# CTRL_MODULE_CORE_PAD register map
Vendor: Texas Instruments
Registers are 32-bit, access per field, reset 0x10F010F unless marked. A register's access mark holds for its fields unless they carry their own. Offsets are as the file gives them; [hi:lo] are bit positions; 'fields as' and 'values as' point back to an identical list.

## CTRL_MODULE_CORE_PAD (part 2 of 7)
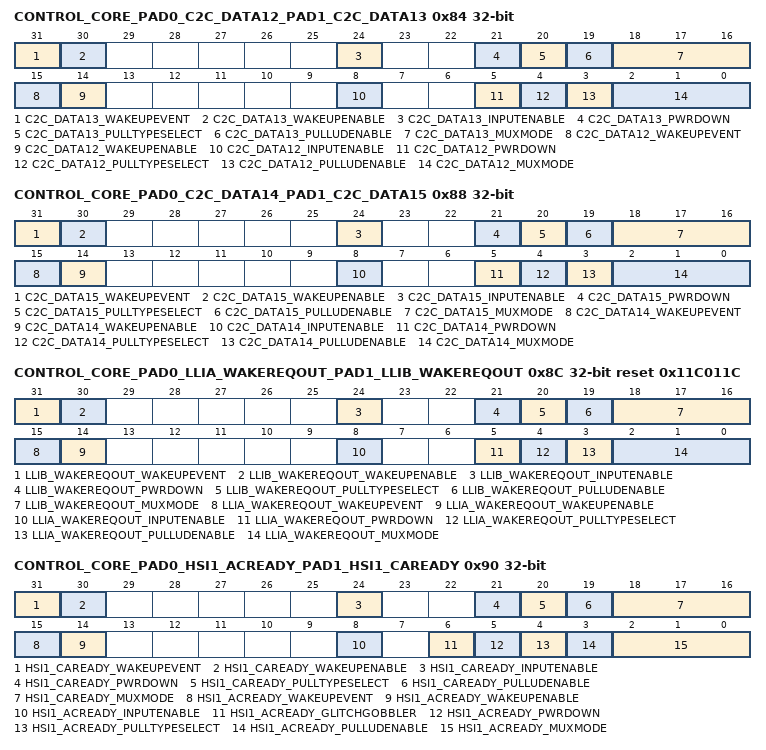
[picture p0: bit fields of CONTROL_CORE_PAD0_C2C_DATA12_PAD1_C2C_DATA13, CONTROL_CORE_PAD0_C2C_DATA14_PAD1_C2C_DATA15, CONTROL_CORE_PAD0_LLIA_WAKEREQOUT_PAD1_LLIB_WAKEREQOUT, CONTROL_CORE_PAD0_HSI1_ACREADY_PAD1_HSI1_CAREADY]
0x84 CONTROL_CORE_PAD0_C2C_DATA12_PAD1_C2C_DATA13 — Register control for Pads c2c_data12 and c2c_data13 Access conditions. Read: unrestricted, Write: unrestricted
  [31] C2C_DATA13_WAKEUPEVENT ro — Pad_x wake-up event status latched in the IO
    1=WakeUp (A wake-up event occurred); 0=No wake-up event occurred
  [30] C2C_DATA13_WAKEUPENABLE rw — Input pad wake-up enable
    0=DetectLow (wake-up detection is disabled); 1=DetectLowHigh (wake-up detection is enabled)
  [24] C2C_DATA13_INPUTENABLE rw — Input enable value for pad c2c_data13
    0=InputBufferDisabled (Input buffer of IO cell is disabled); 1=InputBufferEnabled (Input buffer of IO cell is enabled)
  [21] C2C_DATA13_PWRDOWN rw — Power Down setting for pad c2c_data13
    0=PwrDownDisabled (IO cell power is ON); 1=PwrDownEnabled (IO cell power is OFF)
  [20] C2C_DATA13_PULLTYPESELECT rw — Pull-Up/Down selection for pad c2c_data13
    0=Pull-Down selected; 1=Pull-Up selected
  [19] C2C_DATA13_PULLUDENABLE rw — Pull-Up/Down enable for pad c2c_data13
    0=PullDisabled (Pull-Up/Down disabled); 1=PullEnabled (Pull-Up/Down enabled)
  [18:16] C2C_DATA13_MUXMODE rw — Functional multiplexing selection for pad c2c_data13
    0=SEL_C2C_DATA13 (Reserved); 6=SEL_GPIO4_118 (Select gpio4_118); 4=SEL_GPMC_A21 (Select gpmc_a21); 7=SEL_SAFE_MODE_CORE35 (Select safe_mode_core35); 5=SEL_HW_DBG29 (Select hw_dbg29)
  [15] C2C_DATA12_WAKEUPEVENT ro — Pad_x wake-up event status latched in the IO
    values as C2C_DATA13_WAKEUPEVENT
  [14] C2C_DATA12_WAKEUPENABLE rw — Input pad wake-up enable
    values as C2C_DATA13_WAKEUPENABLE
  [8] C2C_DATA12_INPUTENABLE rw — Input enable value for pad c2c_data12
    values as C2C_DATA13_INPUTENABLE
  [5] C2C_DATA12_PWRDOWN rw — Power Down setting for pad c2c_data12
    values as C2C_DATA13_PWRDOWN
  [4] C2C_DATA12_PULLTYPESELECT rw — Pull-Up/Down selection for pad c2c_data12
    0=Pull-Down selected; 1=Pull-Up selected
  [3] C2C_DATA12_PULLUDENABLE rw — Pull-Up/Down enable for pad c2c_data12
    values as C2C_DATA13_PULLUDENABLE
  [2:0] C2C_DATA12_MUXMODE rw — Functional multiplexing selection for pad c2c_data12
    0=SEL_C2C_DATA12 (Reserved); 6=SEL_GPIO4_117 (Select gpio4_117); 4=SEL_GPMC_A20 (Select gpmc_a20); 7=SEL_SAFE_MODE_CORE34 (Select safe_mode_core34); 5=SEL_HW_DBG28 (Select hw_dbg28)
0x88 CONTROL_CORE_PAD0_C2C_DATA14_PAD1_C2C_DATA15 — Register control for Pads c2c_data14 and c2c_data15 Access conditions. Read: unrestricted, Write: unrestricted
  [31] C2C_DATA15_WAKEUPEVENT ro — Pad_x wake-up event status latched in the IO
    values as CONTROL_CORE_PAD0_C2C_DATA12_PAD1_C2C_DATA13.C2C_DATA13_WAKEUPEVENT
  [30] C2C_DATA15_WAKEUPENABLE rw — Input pad wake-up enable
    values as CONTROL_CORE_PAD0_C2C_DATA12_PAD1_C2C_DATA13.C2C_DATA13_WAKEUPENABLE
  [24] C2C_DATA15_INPUTENABLE rw — Input enable value for pad c2c_data15
    values as CONTROL_CORE_PAD0_C2C_DATA12_PAD1_C2C_DATA13.C2C_DATA13_INPUTENABLE
  [21] C2C_DATA15_PWRDOWN rw — Power Down setting for pad c2c_data15
    values as CONTROL_CORE_PAD0_C2C_DATA12_PAD1_C2C_DATA13.C2C_DATA13_PWRDOWN
  [20] C2C_DATA15_PULLTYPESELECT rw — Pull-Up/Down selection for pad c2c_data15
    0=Pull-Down selected; 1=Pull-Up selected
  [19] C2C_DATA15_PULLUDENABLE rw — Pull-Up/Down enable for pad c2c_data15
    values as CONTROL_CORE_PAD0_C2C_DATA12_PAD1_C2C_DATA13.C2C_DATA13_PULLUDENABLE
  [18:16] C2C_DATA15_MUXMODE rw — Functional multiplexing selection for pad c2c_data15
    0=SEL_C2C_DATA15 (Reserved); 6=SEL_GPIO4_120 (Select gpio4_120); 4=SEL_GPMC_A23 (Select gpmc_a23); 7=SEL_SAFE_MODE_CORE37 (Select safe_mode_core37); 5=SEL_HW_DBG31 (Select hw_dbg31)
  [15] C2C_DATA14_WAKEUPEVENT ro — Pad_x wake-up event status latched in the IO
    values as CONTROL_CORE_PAD0_C2C_DATA12_PAD1_C2C_DATA13.C2C_DATA13_WAKEUPEVENT
  [14] C2C_DATA14_WAKEUPENABLE rw — Input pad wake-up enable
    values as CONTROL_CORE_PAD0_C2C_DATA12_PAD1_C2C_DATA13.C2C_DATA13_WAKEUPENABLE
  [8] C2C_DATA14_INPUTENABLE rw — Input enable value for pad c2c_data14
    values as CONTROL_CORE_PAD0_C2C_DATA12_PAD1_C2C_DATA13.C2C_DATA13_INPUTENABLE
  [5] C2C_DATA14_PWRDOWN rw — Power Down setting for pad c2c_data14
    values as CONTROL_CORE_PAD0_C2C_DATA12_PAD1_C2C_DATA13.C2C_DATA13_PWRDOWN
  [4] C2C_DATA14_PULLTYPESELECT rw — Pull-Up/Down selection for pad c2c_data14
    0=Pull-Down selected; 1=Pull-Up selected
  [3] C2C_DATA14_PULLUDENABLE rw — Pull-Up/Down enable for pad c2c_data14
    values as CONTROL_CORE_PAD0_C2C_DATA12_PAD1_C2C_DATA13.C2C_DATA13_PULLUDENABLE
  [2:0] C2C_DATA14_MUXMODE rw — Functional multiplexing selection for pad c2c_data14
    0=SEL_C2C_DATA14 (Reserved); 6=SEL_GPIO4_119 (Select gpio4_119); 4=SEL_GPMC_A22 (Select gpmc_a22); 7=SEL_SAFE_MODE_CORE36 (Select safe_mode_core36); 5=SEL_HW_DBG30 (Select hw_dbg30)
0x8C CONTROL_CORE_PAD0_LLIA_WAKEREQOUT_PAD1_LLIB_WAKEREQOUT reset 0x11C011C — Register control for Pads llia_wakereqout and llib_wakereqout Access conditions. Read: unrestricted, Write: unrestricted
  [31] LLIB_WAKEREQOUT_WAKEUPEVENT ro — Pad_x wake-up event status latched in the IO
    values as CONTROL_CORE_PAD0_C2C_DATA12_PAD1_C2C_DATA13.C2C_DATA13_WAKEUPEVENT
  [30] LLIB_WAKEREQOUT_WAKEUPENABLE rw — Input pad wake-up enable
    values as CONTROL_CORE_PAD0_C2C_DATA12_PAD1_C2C_DATA13.C2C_DATA13_WAKEUPENABLE
  [24] LLIB_WAKEREQOUT_INPUTENABLE rw — Input enable value for pad llib_wakereqout
    values as CONTROL_CORE_PAD0_C2C_DATA12_PAD1_C2C_DATA13.C2C_DATA13_INPUTENABLE
  [21] LLIB_WAKEREQOUT_PWRDOWN rw — Power Down setting for pad llib_wakereqout
    values as CONTROL_CORE_PAD0_C2C_DATA12_PAD1_C2C_DATA13.C2C_DATA13_PWRDOWN
  [20] LLIB_WAKEREQOUT_PULLTYPESELECT rw — Pull-Up/Down selection for pad llib_wakereqout
    0=Pull-Down selected; 1=Pull-Up selected
  [19] LLIB_WAKEREQOUT_PULLUDENABLE rw — Pull-Up/Down enable for pad llib_wakereqout
    values as CONTROL_CORE_PAD0_C2C_DATA12_PAD1_C2C_DATA13.C2C_DATA13_PULLUDENABLE
  [18:16] LLIB_WAKEREQOUT_MUXMODE rw — Functional multiplexing selection for pad llib_wakereqout
    0=SEL_LLIB_WAKEREQOUT (Select llib_wakereqout); 4=SEL_GPMC_NCS0 (Select gpmc_ncs0); 7=SEL_SAFE_MODE_CORE38 (Select safe_mode_core38); 6=SEL_GPIO2_32 (Select gpio2_32)
  [15] LLIA_WAKEREQOUT_WAKEUPEVENT ro — Pad_x wake-up event status latched in the IO
    values as CONTROL_CORE_PAD0_C2C_DATA12_PAD1_C2C_DATA13.C2C_DATA13_WAKEUPEVENT
  [14] LLIA_WAKEREQOUT_WAKEUPENABLE rw — Input pad wake-up enable
    values as CONTROL_CORE_PAD0_C2C_DATA12_PAD1_C2C_DATA13.C2C_DATA13_WAKEUPENABLE
  [8] LLIA_WAKEREQOUT_INPUTENABLE rw — Input enable value for pad llia_wakereqout
    values as CONTROL_CORE_PAD0_C2C_DATA12_PAD1_C2C_DATA13.C2C_DATA13_INPUTENABLE
  [5] LLIA_WAKEREQOUT_PWRDOWN rw — Power Down setting for pad llia_wakereqout
    values as CONTROL_CORE_PAD0_C2C_DATA12_PAD1_C2C_DATA13.C2C_DATA13_PWRDOWN
  [4] LLIA_WAKEREQOUT_PULLTYPESELECT rw — Pull-Up/Down selection for pad llia_wakereqout
    0=Pull-Down selected; 1=Pull-Up selected
  [3] LLIA_WAKEREQOUT_PULLUDENABLE rw — Pull-Up/Down enable for pad llia_wakereqout
    values as CONTROL_CORE_PAD0_C2C_DATA12_PAD1_C2C_DATA13.C2C_DATA13_PULLUDENABLE
  [2:0] LLIA_WAKEREQOUT_MUXMODE rw — Functional multiplexing selection for pad llia_wakereqout
    0=SEL_LLIA_WAKEREQOUT (Select llia_wakereqout); 1=SEL_C2C_WAKEREQOUT (Select c2c_wakereqout); 4=SEL_GPMC_WAIT0 (Select gpmc_wait0); 7=SEL_SAFE_MODE_CORE39 (Select safe_mode_core39); 6=SEL_GPIO2_45 (Select gpio2_45)
0x90 CONTROL_CORE_PAD0_HSI1_ACREADY_PAD1_HSI1_CAREADY — Register control for Pads hsi1_acready and hsi1_caready Access conditions. Read: unrestricted, Write: unrestricted
  [31] HSI1_CAREADY_WAKEUPEVENT ro — Pad_x wake-up event status latched in the IO
    values as CONTROL_CORE_PAD0_C2C_DATA12_PAD1_C2C_DATA13.C2C_DATA13_WAKEUPEVENT
  [30] HSI1_CAREADY_WAKEUPENABLE rw — Input pad wake-up enable
    values as CONTROL_CORE_PAD0_C2C_DATA12_PAD1_C2C_DATA13.C2C_DATA13_WAKEUPENABLE
  [24] HSI1_CAREADY_INPUTENABLE rw — Input enable value for pad hsi1_caready
    values as CONTROL_CORE_PAD0_C2C_DATA12_PAD1_C2C_DATA13.C2C_DATA13_INPUTENABLE
  [21] HSI1_CAREADY_PWRDOWN rw — Power Down setting for pad hsi1_caready
    values as CONTROL_CORE_PAD0_C2C_DATA12_PAD1_C2C_DATA13.C2C_DATA13_PWRDOWN
  [20] HSI1_CAREADY_PULLTYPESELECT rw — Pull-Up/Down selection for pad hsi1_caready
    0=Pull-Down selected; 1=Pull-Up selected
  [19] HSI1_CAREADY_PULLUDENABLE rw — Pull-Up/Down enable for pad hsi1_caready
    values as CONTROL_CORE_PAD0_C2C_DATA12_PAD1_C2C_DATA13.C2C_DATA13_PULLUDENABLE
  [18:16] HSI1_CAREADY_MUXMODE rw — Functional multiplexing selection for pad hsi1_caready
    0=SEL_HSI1_CAREADY (Select hsi1_caready); 3=SEL_USBB2_ULPITLL_NXT (Select usbb2_ulpitll_nxt); 7=SEL_SAFE_MODE_CORE41 (Select safe_mode_core41); 6=SEL_GPIO3_65 (Select gpio3_65)
  [15] HSI1_ACREADY_WAKEUPEVENT ro — Pad_x wake-up event status latched in the IO
    values as CONTROL_CORE_PAD0_C2C_DATA12_PAD1_C2C_DATA13.C2C_DATA13_WAKEUPEVENT
  [14] HSI1_ACREADY_WAKEUPENABLE rw — Input pad wake-up enable
    values as CONTROL_CORE_PAD0_C2C_DATA12_PAD1_C2C_DATA13.C2C_DATA13_WAKEUPENABLE
  [8] HSI1_ACREADY_INPUTENABLE rw — Input enable value for pad hsi1_acready
    values as CONTROL_CORE_PAD0_C2C_DATA12_PAD1_C2C_DATA13.C2C_DATA13_INPUTENABLE
  [6] HSI1_ACREADY_GLITCHGOBBLER rw — Glitch Gobbler setting for pad hsi1_acready
    0=GlitchGobblerDisabled (IO do not Filter glitch from outside); 1=GlitchGobblerEnabled (IO Filter glitch from outside)
  [5] HSI1_ACREADY_PWRDOWN rw — Power Down setting for pad hsi1_acready
    values as CONTROL_CORE_PAD0_C2C_DATA12_PAD1_C2C_DATA13.C2C_DATA13_PWRDOWN
  [4] HSI1_ACREADY_PULLTYPESELECT rw — Pull-Up/Down selection for pad hsi1_acready
    0=Pull-Down selected; 1=Pull-Up selected
  [3] HSI1_ACREADY_PULLUDENABLE rw — Pull-Up/Down enable for pad hsi1_acready
    values as CONTROL_CORE_PAD0_C2C_DATA12_PAD1_C2C_DATA13.C2C_DATA13_PULLUDENABLE
  [2:0] HSI1_ACREADY_MUXMODE rw — Functional multiplexing selection for pad hsi1_acready
    0=SEL_HSI1_ACREADY (Select hsi1_acready); 1=SEL_CAM_STROBE (Select cam_strobe); 3=SEL_USBB2_ULPITLL_CLK (Select usbb2_ulpitll_clk); 7=SEL_SAFE_MODE_CORE40 (Select safe_mode_core40); 6=SEL_GPIO3_64 (Select gpio3_64)
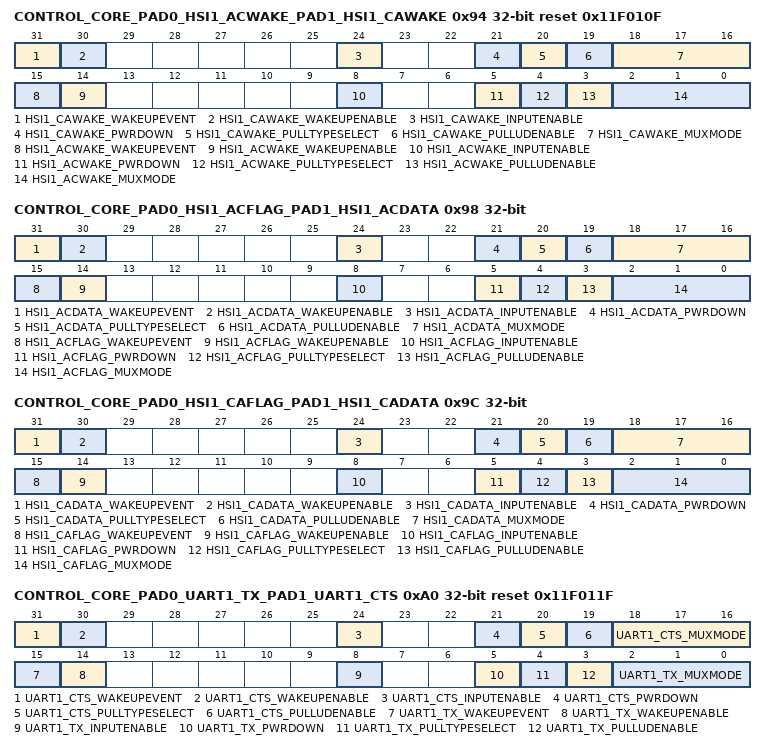
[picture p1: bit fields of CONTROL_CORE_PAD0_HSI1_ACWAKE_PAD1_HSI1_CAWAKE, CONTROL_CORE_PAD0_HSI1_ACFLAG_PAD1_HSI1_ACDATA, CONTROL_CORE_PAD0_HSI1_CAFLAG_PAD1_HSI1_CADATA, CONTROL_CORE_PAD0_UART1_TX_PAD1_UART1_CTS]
0x94 CONTROL_CORE_PAD0_HSI1_ACWAKE_PAD1_HSI1_CAWAKE reset 0x11F010F — Register control for Pads hsi1_acwake and hsi1_cawake Access conditions. Read: unrestricted, Write: unrestricted
  [31] HSI1_CAWAKE_WAKEUPEVENT ro — Pad_x wake-up event status latched in the IO
    values as CONTROL_CORE_PAD0_C2C_DATA12_PAD1_C2C_DATA13.C2C_DATA13_WAKEUPEVENT
  [30] HSI1_CAWAKE_WAKEUPENABLE rw — Input pad wake-up enable
    values as CONTROL_CORE_PAD0_C2C_DATA12_PAD1_C2C_DATA13.C2C_DATA13_WAKEUPENABLE
  [24] HSI1_CAWAKE_INPUTENABLE rw — Input enable value for pad hsi1_cawake
    values as CONTROL_CORE_PAD0_C2C_DATA12_PAD1_C2C_DATA13.C2C_DATA13_INPUTENABLE
  [21] HSI1_CAWAKE_PWRDOWN rw — Power Down setting for pad hsi1_cawake
    values as CONTROL_CORE_PAD0_C2C_DATA12_PAD1_C2C_DATA13.C2C_DATA13_PWRDOWN
  [20] HSI1_CAWAKE_PULLTYPESELECT rw — Pull-Up/Down selection for pad hsi1_cawake
    0=Pull-Down selected; 1=Pull-Up selected
  [19] HSI1_CAWAKE_PULLUDENABLE rw — Pull-Up/Down enable for pad hsi1_cawake
    values as CONTROL_CORE_PAD0_C2C_DATA12_PAD1_C2C_DATA13.C2C_DATA13_PULLUDENABLE
  [18:16] HSI1_CAWAKE_MUXMODE rw — Functional multiplexing selection for pad hsi1_cawake
    0=SEL_HSI1_CAWAKE (Select hsi1_cawake); 3=SEL_USBB2_ULPITLL_STP (Select usbb2_ulpitll_stp); 7=SEL_SAFE_MODE_CORE43 (Select safe_mode_core43); 6=SEL_GPIO3_67 (Select gpio3_67)
  [15] HSI1_ACWAKE_WAKEUPEVENT ro — Pad_x wake-up event status latched in the IO
    values as CONTROL_CORE_PAD0_C2C_DATA12_PAD1_C2C_DATA13.C2C_DATA13_WAKEUPEVENT
  [14] HSI1_ACWAKE_WAKEUPENABLE rw — Input pad wake-up enable
    values as CONTROL_CORE_PAD0_C2C_DATA12_PAD1_C2C_DATA13.C2C_DATA13_WAKEUPENABLE
  [8] HSI1_ACWAKE_INPUTENABLE rw — Input enable value for pad hsi1_acwake
    values as CONTROL_CORE_PAD0_C2C_DATA12_PAD1_C2C_DATA13.C2C_DATA13_INPUTENABLE
  [5] HSI1_ACWAKE_PWRDOWN rw — Power Down setting for pad hsi1_acwake
    values as CONTROL_CORE_PAD0_C2C_DATA12_PAD1_C2C_DATA13.C2C_DATA13_PWRDOWN
  [4] HSI1_ACWAKE_PULLTYPESELECT rw — Pull-Up/Down selection for pad hsi1_acwake
    0=Pull-Down selected; 1=Pull-Up selected
  [3] HSI1_ACWAKE_PULLUDENABLE rw — Pull-Up/Down enable for pad hsi1_acwake
    values as CONTROL_CORE_PAD0_C2C_DATA12_PAD1_C2C_DATA13.C2C_DATA13_PULLUDENABLE
  [2:0] HSI1_ACWAKE_MUXMODE rw — Functional multiplexing selection for pad hsi1_acwake
    0=SEL_HSI1_ACWAKE (Select hsi1_acwake); 3=SEL_USBB2_ULPITLL_DIR (Select usbb2_ulpitll_dir); 7=SEL_SAFE_MODE_CORE42 (Select safe_mode_core42); 6=SEL_GPIO3_66 (Select gpio3_66)
0x98 CONTROL_CORE_PAD0_HSI1_ACFLAG_PAD1_HSI1_ACDATA — Register control for Pads hsi1_acflag and hsi1_acdata Access conditions. Read: unrestricted, Write: unrestricted
  [31] HSI1_ACDATA_WAKEUPEVENT ro — Pad_x wake-up event status latched in the IO
    values as CONTROL_CORE_PAD0_C2C_DATA12_PAD1_C2C_DATA13.C2C_DATA13_WAKEUPEVENT
  [30] HSI1_ACDATA_WAKEUPENABLE rw — Input pad wake-up enable
    values as CONTROL_CORE_PAD0_C2C_DATA12_PAD1_C2C_DATA13.C2C_DATA13_WAKEUPENABLE
  [24] HSI1_ACDATA_INPUTENABLE rw — Input enable value for pad hsi1_acdata
    values as CONTROL_CORE_PAD0_C2C_DATA12_PAD1_C2C_DATA13.C2C_DATA13_INPUTENABLE
  [21] HSI1_ACDATA_PWRDOWN rw — Power Down setting for pad hsi1_acdata
    values as CONTROL_CORE_PAD0_C2C_DATA12_PAD1_C2C_DATA13.C2C_DATA13_PWRDOWN
  [20] HSI1_ACDATA_PULLTYPESELECT rw — Pull-Up/Down selection for pad hsi1_acdata
    0=Pull-Down selected; 1=Pull-Up selected
  [19] HSI1_ACDATA_PULLUDENABLE rw — Pull-Up/Down enable for pad hsi1_acdata
    values as CONTROL_CORE_PAD0_C2C_DATA12_PAD1_C2C_DATA13.C2C_DATA13_PULLUDENABLE
  [18:16] HSI1_ACDATA_MUXMODE rw — Functional multiplexing selection for pad hsi1_acdata
    0=SEL_HSI1_ACDATA (Select hsi1_acdata); 3=SEL_USBB2_ULPITLL_DATA1 (Select usbb2_ulpitll_data1); 7=SEL_SAFE_MODE_CORE45 (Select safe_mode_core45); 6=SEL_GPIO3_69 (Select gpio3_69)
  [15] HSI1_ACFLAG_WAKEUPEVENT ro — Pad_x wake-up event status latched in the IO
    values as CONTROL_CORE_PAD0_C2C_DATA12_PAD1_C2C_DATA13.C2C_DATA13_WAKEUPEVENT
  [14] HSI1_ACFLAG_WAKEUPENABLE rw — Input pad wake-up enable
    values as CONTROL_CORE_PAD0_C2C_DATA12_PAD1_C2C_DATA13.C2C_DATA13_WAKEUPENABLE
  [8] HSI1_ACFLAG_INPUTENABLE rw — Input enable value for pad hsi1_acflag
    values as CONTROL_CORE_PAD0_C2C_DATA12_PAD1_C2C_DATA13.C2C_DATA13_INPUTENABLE
  [5] HSI1_ACFLAG_PWRDOWN rw — Power Down setting for pad hsi1_acflag
    values as CONTROL_CORE_PAD0_C2C_DATA12_PAD1_C2C_DATA13.C2C_DATA13_PWRDOWN
  [4] HSI1_ACFLAG_PULLTYPESELECT rw — Pull-Up/Down selection for pad hsi1_acflag
    0=Pull-Down selected; 1=Pull-Up selected
  [3] HSI1_ACFLAG_PULLUDENABLE rw — Pull-Up/Down enable for pad hsi1_acflag
    values as CONTROL_CORE_PAD0_C2C_DATA12_PAD1_C2C_DATA13.C2C_DATA13_PULLUDENABLE
  [2:0] HSI1_ACFLAG_MUXMODE rw — Functional multiplexing selection for pad hsi1_acflag
    0=SEL_HSI1_ACFLAG (Select hsi1_acflag); 3=SEL_USBB2_ULPITLL_DATA0 (Select usbb2_ulpitll_data0); 7=SEL_SAFE_MODE_CORE44 (Select safe_mode_core44); 6=SEL_GPIO3_68 (Select gpio3_68)
0x9C CONTROL_CORE_PAD0_HSI1_CAFLAG_PAD1_HSI1_CADATA — Register control for Pads hsi1_caflag and hsi1_cadata Access conditions. Read: unrestricted, Write: unrestricted
  [31] HSI1_CADATA_WAKEUPEVENT ro — Pad_x wake-up event status latched in the IO
    values as CONTROL_CORE_PAD0_C2C_DATA12_PAD1_C2C_DATA13.C2C_DATA13_WAKEUPEVENT
  [30] HSI1_CADATA_WAKEUPENABLE rw — Input pad wake-up enable
    values as CONTROL_CORE_PAD0_C2C_DATA12_PAD1_C2C_DATA13.C2C_DATA13_WAKEUPENABLE
  [24] HSI1_CADATA_INPUTENABLE rw — Input enable value for pad hsi1_cadata
    values as CONTROL_CORE_PAD0_C2C_DATA12_PAD1_C2C_DATA13.C2C_DATA13_INPUTENABLE
  [21] HSI1_CADATA_PWRDOWN rw — Power Down setting for pad hsi1_cadata
    values as CONTROL_CORE_PAD0_C2C_DATA12_PAD1_C2C_DATA13.C2C_DATA13_PWRDOWN
  [20] HSI1_CADATA_PULLTYPESELECT rw — Pull-Up/Down selection for pad hsi1_cadata
    0=Pull-Down selected; 1=Pull-Up selected
  [19] HSI1_CADATA_PULLUDENABLE rw — Pull-Up/Down enable for pad hsi1_cadata
    values as CONTROL_CORE_PAD0_C2C_DATA12_PAD1_C2C_DATA13.C2C_DATA13_PULLUDENABLE
  [18:16] HSI1_CADATA_MUXMODE rw — Functional multiplexing selection for pad hsi1_cadata
    0=SEL_HSI1_CADATA (Select hsi1_cadata); 3=SEL_USBB2_ULPITLL_DATA3 (Select usbb2_ulpitll_data3); 7=SEL_SAFE_MODE_CORE47 (Select safe_mode_core47); 6=SEL_GPIO3_71 (Select gpio3_71)
  [15] HSI1_CAFLAG_WAKEUPEVENT ro — Pad_x wake-up event status latched in the IO
    values as CONTROL_CORE_PAD0_C2C_DATA12_PAD1_C2C_DATA13.C2C_DATA13_WAKEUPEVENT
  [14] HSI1_CAFLAG_WAKEUPENABLE rw — Input pad wake-up enable
    values as CONTROL_CORE_PAD0_C2C_DATA12_PAD1_C2C_DATA13.C2C_DATA13_WAKEUPENABLE
  [8] HSI1_CAFLAG_INPUTENABLE rw — Input enable value for pad hsi1_caflag
    values as CONTROL_CORE_PAD0_C2C_DATA12_PAD1_C2C_DATA13.C2C_DATA13_INPUTENABLE
  [5] HSI1_CAFLAG_PWRDOWN rw — Power Down setting for pad hsi1_caflag
    values as CONTROL_CORE_PAD0_C2C_DATA12_PAD1_C2C_DATA13.C2C_DATA13_PWRDOWN
  [4] HSI1_CAFLAG_PULLTYPESELECT rw — Pull-Up/Down selection for pad hsi1_caflag
    0=Pull-Down selected; 1=Pull-Up selected
  [3] HSI1_CAFLAG_PULLUDENABLE rw — Pull-Up/Down enable for pad hsi1_caflag
    values as CONTROL_CORE_PAD0_C2C_DATA12_PAD1_C2C_DATA13.C2C_DATA13_PULLUDENABLE
  [2:0] HSI1_CAFLAG_MUXMODE rw — Functional multiplexing selection for pad hsi1_caflag
    0=SEL_HSI1_CAFLAG (Select hsi1_caflag); 3=SEL_USBB2_ULPITLL_DATA2 (Select usbb2_ulpitll_data2); 7=SEL_SAFE_MODE_CORE46 (Select safe_mode_core46); 6=SEL_GPIO3_70 (Select gpio3_70)
0xA0 CONTROL_CORE_PAD0_UART1_TX_PAD1_UART1_CTS reset 0x11F011F — Register control for Pads uart1_tx and uart1_cts Access conditions. Read: unrestricted, Write: unrestricted
  [31] UART1_CTS_WAKEUPEVENT ro — Pad_x wake-up event status latched in the IO
    values as CONTROL_CORE_PAD0_C2C_DATA12_PAD1_C2C_DATA13.C2C_DATA13_WAKEUPEVENT
  [30] UART1_CTS_WAKEUPENABLE rw — Input pad wake-up enable
    values as CONTROL_CORE_PAD0_C2C_DATA12_PAD1_C2C_DATA13.C2C_DATA13_WAKEUPENABLE
  [24] UART1_CTS_INPUTENABLE rw — Input enable value for pad uart1_cts
    values as CONTROL_CORE_PAD0_C2C_DATA12_PAD1_C2C_DATA13.C2C_DATA13_INPUTENABLE
  [21] UART1_CTS_PWRDOWN rw — Power Down setting for pad uart1_cts
    values as CONTROL_CORE_PAD0_C2C_DATA12_PAD1_C2C_DATA13.C2C_DATA13_PWRDOWN
  [20] UART1_CTS_PULLTYPESELECT rw — Pull-Up/Down selection for pad uart1_cts
    0=Pull-Down selected; 1=Pull-Up selected
  [19] UART1_CTS_PULLUDENABLE rw — Pull-Up/Down enable for pad uart1_cts
    values as CONTROL_CORE_PAD0_C2C_DATA12_PAD1_C2C_DATA13.C2C_DATA13_PULLUDENABLE
  [18:16] UART1_CTS_MUXMODE rw — Functional multiplexing selection for pad uart1_cts
    0=SEL_UART1_CTS (Select uart1_cts); 3=SEL_USBB2_ULPITLL_DATA5 (Select usbb2_ulpitll_data5); 7=SEL_SAFE_MODE_CORE49 (Select safe_mode_core49); 4=SEL_GPMC_WAIT3 (Select gpmc_wait3); 6=SEL_GPIO3_73 (Select gpio3_73)
  [15] UART1_TX_WAKEUPEVENT ro — Pad_x wake-up event status latched in the IO
    values as CONTROL_CORE_PAD0_C2C_DATA12_PAD1_C2C_DATA13.C2C_DATA13_WAKEUPEVENT
  [14] UART1_TX_WAKEUPENABLE rw — Input pad wake-up enable
    values as CONTROL_CORE_PAD0_C2C_DATA12_PAD1_C2C_DATA13.C2C_DATA13_WAKEUPENABLE
  [8] UART1_TX_INPUTENABLE rw — Input enable value for pad uart1_tx
    values as CONTROL_CORE_PAD0_C2C_DATA12_PAD1_C2C_DATA13.C2C_DATA13_INPUTENABLE
  [5] UART1_TX_PWRDOWN rw — Power Down setting for pad uart1_tx
    values as CONTROL_CORE_PAD0_C2C_DATA12_PAD1_C2C_DATA13.C2C_DATA13_PWRDOWN
  [4] UART1_TX_PULLTYPESELECT rw — Pull-Up/Down selection for pad uart1_tx
    0=Pull-Down selected; 1=Pull-Up selected
  [3] UART1_TX_PULLUDENABLE rw — Pull-Up/Down enable for pad uart1_tx
    values as CONTROL_CORE_PAD0_C2C_DATA12_PAD1_C2C_DATA13.C2C_DATA13_PULLUDENABLE
  [2:0] UART1_TX_MUXMODE rw — Functional multiplexing selection for pad uart1_tx
    0=SEL_UART1_TX (Select uart1_tx); 3=SEL_USBB2_ULPITLL_DATA4 (Select usbb2_ulpitll_data4); 7=SEL_SAFE_MODE_CORE48 (Select safe_mode_core48); 6=SEL_GPIO3_72 (Select gpio3_72)
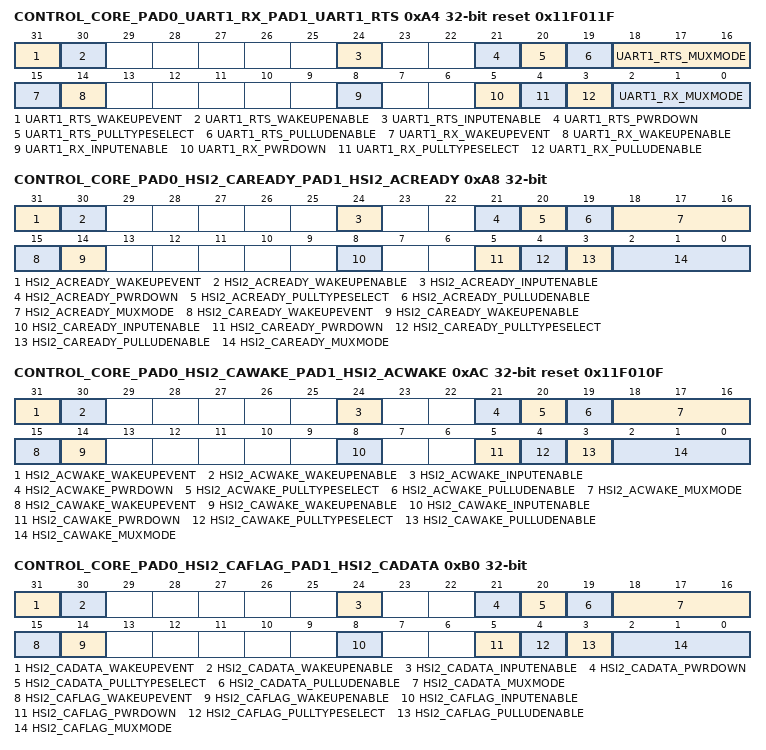
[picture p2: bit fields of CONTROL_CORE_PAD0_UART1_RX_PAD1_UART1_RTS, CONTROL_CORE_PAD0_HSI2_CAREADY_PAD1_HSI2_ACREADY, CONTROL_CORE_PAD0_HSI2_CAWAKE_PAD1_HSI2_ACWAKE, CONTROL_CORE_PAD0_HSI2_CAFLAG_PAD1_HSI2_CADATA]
0xA4 CONTROL_CORE_PAD0_UART1_RX_PAD1_UART1_RTS reset 0x11F011F — Register control for Pads uart1_rx and uart1_rts Access conditions. Read: unrestricted, Write: unrestricted
  [31] UART1_RTS_WAKEUPEVENT ro — Pad_x wake-up event status latched in the IO
    values as CONTROL_CORE_PAD0_C2C_DATA12_PAD1_C2C_DATA13.C2C_DATA13_WAKEUPEVENT
  [30] UART1_RTS_WAKEUPENABLE rw — Input pad wake-up enable
    values as CONTROL_CORE_PAD0_C2C_DATA12_PAD1_C2C_DATA13.C2C_DATA13_WAKEUPENABLE
  [24] UART1_RTS_INPUTENABLE rw — Input enable value for pad uart1_rts
    values as CONTROL_CORE_PAD0_C2C_DATA12_PAD1_C2C_DATA13.C2C_DATA13_INPUTENABLE
  [21] UART1_RTS_PWRDOWN rw — Power Down setting for pad uart1_rts
    values as CONTROL_CORE_PAD0_C2C_DATA12_PAD1_C2C_DATA13.C2C_DATA13_PWRDOWN
  [20] UART1_RTS_PULLTYPESELECT rw — Pull-Up/Down selection for pad uart1_rts
    0=Pull-Down selected; 1=Pull-Up selected
  [19] UART1_RTS_PULLUDENABLE rw — Pull-Up/Down enable for pad uart1_rts
    values as CONTROL_CORE_PAD0_C2C_DATA12_PAD1_C2C_DATA13.C2C_DATA13_PULLUDENABLE
  [18:16] UART1_RTS_MUXMODE rw — Functional multiplexing selection for pad uart1_rts
    0=SEL_UART1_RTS (Select uart1_rts); 3=SEL_USBB2_ULPITLL_DATA7 (Select usbb2_ulpitll_data7); 7=SEL_SAFE_MODE_CORE51 (Select safe_mode_core51); 4=SEL_GPMC_NCS7 (Select gpmc_ncs7); 6=SEL_GPIO3_75 (Select gpio3_75)
  [15] UART1_RX_WAKEUPEVENT ro — Pad_x wake-up event status latched in the IO
    values as CONTROL_CORE_PAD0_C2C_DATA12_PAD1_C2C_DATA13.C2C_DATA13_WAKEUPEVENT
  [14] UART1_RX_WAKEUPENABLE rw — Input pad wake-up enable
    values as CONTROL_CORE_PAD0_C2C_DATA12_PAD1_C2C_DATA13.C2C_DATA13_WAKEUPENABLE
  [8] UART1_RX_INPUTENABLE rw — Input enable value for pad uart1_rx
    values as CONTROL_CORE_PAD0_C2C_DATA12_PAD1_C2C_DATA13.C2C_DATA13_INPUTENABLE
  [5] UART1_RX_PWRDOWN rw — Power Down setting for pad uart1_rx
    values as CONTROL_CORE_PAD0_C2C_DATA12_PAD1_C2C_DATA13.C2C_DATA13_PWRDOWN
  [4] UART1_RX_PULLTYPESELECT rw — Pull-Up/Down selection for pad uart1_rx
    0=Pull-Down selected; 1=Pull-Up selected
  [3] UART1_RX_PULLUDENABLE rw — Pull-Up/Down enable for pad uart1_rx
    values as CONTROL_CORE_PAD0_C2C_DATA12_PAD1_C2C_DATA13.C2C_DATA13_PULLUDENABLE
  [2:0] UART1_RX_MUXMODE rw — Functional multiplexing selection for pad uart1_rx
    0=SEL_UART1_RX (Select uart1_rx); 3=SEL_USBB2_ULPITLL_DATA6 (Select usbb2_ulpitll_data6); 7=SEL_SAFE_MODE_CORE50 (Select safe_mode_core50); 6=SEL_GPIO3_74 (Select gpio3_74)
0xA8 CONTROL_CORE_PAD0_HSI2_CAREADY_PAD1_HSI2_ACREADY — Register control for Pads hsi2_caready and hsi2_acready Access conditions. Read: unrestricted, Write: unrestricted
  [31] HSI2_ACREADY_WAKEUPEVENT ro — Pad_x wake-up event status latched in the IO
    values as CONTROL_CORE_PAD0_C2C_DATA12_PAD1_C2C_DATA13.C2C_DATA13_WAKEUPEVENT
  [30] HSI2_ACREADY_WAKEUPENABLE rw — Input pad wake-up enable
    values as CONTROL_CORE_PAD0_C2C_DATA12_PAD1_C2C_DATA13.C2C_DATA13_WAKEUPENABLE
  [24] HSI2_ACREADY_INPUTENABLE rw — Input enable value for pad hsi2_acready
    values as CONTROL_CORE_PAD0_C2C_DATA12_PAD1_C2C_DATA13.C2C_DATA13_INPUTENABLE
  [21] HSI2_ACREADY_PWRDOWN rw — Power Down setting for pad hsi2_acready
    values as CONTROL_CORE_PAD0_C2C_DATA12_PAD1_C2C_DATA13.C2C_DATA13_PWRDOWN
  [20] HSI2_ACREADY_PULLTYPESELECT rw — Pull-Up/Down selection for pad hsi2_acready
    0=Pull-Down selected; 1=Pull-Up selected
  [19] HSI2_ACREADY_PULLUDENABLE rw — Pull-Up/Down enable for pad hsi2_acready
    values as CONTROL_CORE_PAD0_C2C_DATA12_PAD1_C2C_DATA13.C2C_DATA13_PULLUDENABLE
  [18:16] HSI2_ACREADY_MUXMODE rw — Functional multiplexing selection for pad hsi2_acready
    0=SEL_HSI2_ACREADY (Select hsi2_acready); 3=SEL_USBB1_ULPIPHY_NXT (Select usbb1_ulpiphy_nxt); 7=SEL_SAFE_MODE_CORE53 (Select safe_mode_core53); 4=SEL_GPMC_NCS1 (Select gpmc_ncs1); 6=SEL_GPIO3_77 (Select gpio3_77)
  [15] HSI2_CAREADY_WAKEUPEVENT ro — Pad_x wake-up event status latched in the IO
    values as CONTROL_CORE_PAD0_C2C_DATA12_PAD1_C2C_DATA13.C2C_DATA13_WAKEUPEVENT
  [14] HSI2_CAREADY_WAKEUPENABLE rw — Input pad wake-up enable
    values as CONTROL_CORE_PAD0_C2C_DATA12_PAD1_C2C_DATA13.C2C_DATA13_WAKEUPENABLE
  [8] HSI2_CAREADY_INPUTENABLE rw — Input enable value for pad hsi2_caready
    values as CONTROL_CORE_PAD0_C2C_DATA12_PAD1_C2C_DATA13.C2C_DATA13_INPUTENABLE
  [5] HSI2_CAREADY_PWRDOWN rw — Power Down setting for pad hsi2_caready
    values as CONTROL_CORE_PAD0_C2C_DATA12_PAD1_C2C_DATA13.C2C_DATA13_PWRDOWN
  [4] HSI2_CAREADY_PULLTYPESELECT rw — Pull-Up/Down selection for pad hsi2_caready
    0=Pull-Down selected; 1=Pull-Up selected
  [3] HSI2_CAREADY_PULLUDENABLE rw — Pull-Up/Down enable for pad hsi2_caready
    values as CONTROL_CORE_PAD0_C2C_DATA12_PAD1_C2C_DATA13.C2C_DATA13_PULLUDENABLE
  [2:0] HSI2_CAREADY_MUXMODE rw — Functional multiplexing selection for pad hsi2_caready
    0=SEL_HSI2_CAREADY (Select hsi2_caready); 3=SEL_USBB1_ULPIPHY_CLK (Select usbb1_ulpiphy_clk); 7=SEL_SAFE_MODE_CORE52 (Select safe_mode_core52); 4=SEL_GPMC_WAIT1 (Select gpmc_wait1); 6=SEL_GPIO3_76 (Select gpio3_76)
0xAC CONTROL_CORE_PAD0_HSI2_CAWAKE_PAD1_HSI2_ACWAKE reset 0x11F010F — Register control for Pads hsi2_cawake and hsi2_acwake Access conditions. Read: unrestricted, Write: unrestricted
  [31] HSI2_ACWAKE_WAKEUPEVENT ro — Pad_x wake-up event status latched in the IO
    values as CONTROL_CORE_PAD0_C2C_DATA12_PAD1_C2C_DATA13.C2C_DATA13_WAKEUPEVENT
  [30] HSI2_ACWAKE_WAKEUPENABLE rw — Input pad wake-up enable
    values as CONTROL_CORE_PAD0_C2C_DATA12_PAD1_C2C_DATA13.C2C_DATA13_WAKEUPENABLE
  [24] HSI2_ACWAKE_INPUTENABLE rw — Input enable value for pad hsi2_acwake
    values as CONTROL_CORE_PAD0_C2C_DATA12_PAD1_C2C_DATA13.C2C_DATA13_INPUTENABLE
  [21] HSI2_ACWAKE_PWRDOWN rw — Power Down setting for pad hsi2_acwake
    values as CONTROL_CORE_PAD0_C2C_DATA12_PAD1_C2C_DATA13.C2C_DATA13_PWRDOWN
  [20] HSI2_ACWAKE_PULLTYPESELECT rw — Pull-Up/Down selection for pad hsi2_acwake
    0=Pull-Down selected; 1=Pull-Up selected
  [19] HSI2_ACWAKE_PULLUDENABLE rw — Pull-Up/Down enable for pad hsi2_acwake
    values as CONTROL_CORE_PAD0_C2C_DATA12_PAD1_C2C_DATA13.C2C_DATA13_PULLUDENABLE
  [18:16] HSI2_ACWAKE_MUXMODE rw — Functional multiplexing selection for pad hsi2_acwake
    0=SEL_HSI2_ACWAKE (Select hsi2_acwake); 3=SEL_USBB1_ULPIPHY_STP (Select usbb1_ulpiphy_stp); 7=SEL_SAFE_MODE_CORE55 (Select safe_mode_core55); 4=SEL_GPMC_A25 (Select gpmc_a25); 6=SEL_GPIO3_79 (Select gpio3_79)
  [15] HSI2_CAWAKE_WAKEUPEVENT ro — Pad_x wake-up event status latched in the IO
    values as CONTROL_CORE_PAD0_C2C_DATA12_PAD1_C2C_DATA13.C2C_DATA13_WAKEUPEVENT
  [14] HSI2_CAWAKE_WAKEUPENABLE rw — Input pad wake-up enable
    values as CONTROL_CORE_PAD0_C2C_DATA12_PAD1_C2C_DATA13.C2C_DATA13_WAKEUPENABLE
  [8] HSI2_CAWAKE_INPUTENABLE rw — Input enable value for pad hsi2_cawake
    values as CONTROL_CORE_PAD0_C2C_DATA12_PAD1_C2C_DATA13.C2C_DATA13_INPUTENABLE
  [5] HSI2_CAWAKE_PWRDOWN rw — Power Down setting for pad hsi2_cawake
    values as CONTROL_CORE_PAD0_C2C_DATA12_PAD1_C2C_DATA13.C2C_DATA13_PWRDOWN
  [4] HSI2_CAWAKE_PULLTYPESELECT rw — Pull-Up/Down selection for pad hsi2_cawake
    0=Pull-Down selected; 1=Pull-Up selected
  [3] HSI2_CAWAKE_PULLUDENABLE rw — Pull-Up/Down enable for pad hsi2_cawake
    values as CONTROL_CORE_PAD0_C2C_DATA12_PAD1_C2C_DATA13.C2C_DATA13_PULLUDENABLE
  [2:0] HSI2_CAWAKE_MUXMODE rw — Functional multiplexing selection for pad hsi2_cawake
    0=SEL_HSI2_CAWAKE (Select hsi2_cawake); 3=SEL_USBB1_ULPIPHY_DIR (Select usbb1_ulpiphy_dir); 7=SEL_SAFE_MODE_CORE54 (Select safe_mode_core54); 4=SEL_GPMC_A24 (Select gpmc_a24); 6=SEL_GPIO3_78 (Select gpio3_78)
0xB0 CONTROL_CORE_PAD0_HSI2_CAFLAG_PAD1_HSI2_CADATA — Register control for Pads hsi2_caflag and hsi2_cadata Access conditions. Read: unrestricted, Write: unrestricted
  [31] HSI2_CADATA_WAKEUPEVENT ro — Pad_x wake-up event status latched in the IO
    values as CONTROL_CORE_PAD0_C2C_DATA12_PAD1_C2C_DATA13.C2C_DATA13_WAKEUPEVENT
  [30] HSI2_CADATA_WAKEUPENABLE rw — Input pad wake-up enable
    values as CONTROL_CORE_PAD0_C2C_DATA12_PAD1_C2C_DATA13.C2C_DATA13_WAKEUPENABLE
  [24] HSI2_CADATA_INPUTENABLE rw — Input enable value for pad hsi2_cadata
    values as CONTROL_CORE_PAD0_C2C_DATA12_PAD1_C2C_DATA13.C2C_DATA13_INPUTENABLE
  [21] HSI2_CADATA_PWRDOWN rw — Power Down setting for pad hsi2_cadata
    values as CONTROL_CORE_PAD0_C2C_DATA12_PAD1_C2C_DATA13.C2C_DATA13_PWRDOWN
  [20] HSI2_CADATA_PULLTYPESELECT rw — Pull-Up/Down selection for pad hsi2_cadata
    0=Pull-Down selected; 1=Pull-Up selected
  [19] HSI2_CADATA_PULLUDENABLE rw — Pull-Up/Down enable for pad hsi2_cadata
    values as CONTROL_CORE_PAD0_C2C_DATA12_PAD1_C2C_DATA13.C2C_DATA13_PULLUDENABLE
  [18:16] HSI2_CADATA_MUXMODE rw — Functional multiplexing selection for pad hsi2_cadata
    0=SEL_HSI2_CADATA (Select hsi2_cadata); 3=SEL_USBB1_ULPIPHY_DATA1 (Select usbb1_ulpiphy_data1); 7=SEL_SAFE_MODE_CORE57 (Select safe_mode_core57); 4=SEL_GPMC_NCS2 (Select gpmc_ncs2); 6=SEL_GPIO3_81 (Select gpio3_81)
  [15] HSI2_CAFLAG_WAKEUPEVENT ro — Pad_x wake-up event status latched in the IO
    values as CONTROL_CORE_PAD0_C2C_DATA12_PAD1_C2C_DATA13.C2C_DATA13_WAKEUPEVENT
  [14] HSI2_CAFLAG_WAKEUPENABLE rw — Input pad wake-up enable
    values as CONTROL_CORE_PAD0_C2C_DATA12_PAD1_C2C_DATA13.C2C_DATA13_WAKEUPENABLE
  [8] HSI2_CAFLAG_INPUTENABLE rw — Input enable value for pad hsi2_caflag
    values as CONTROL_CORE_PAD0_C2C_DATA12_PAD1_C2C_DATA13.C2C_DATA13_INPUTENABLE
  [5] HSI2_CAFLAG_PWRDOWN rw — Power Down setting for pad hsi2_caflag
    values as CONTROL_CORE_PAD0_C2C_DATA12_PAD1_C2C_DATA13.C2C_DATA13_PWRDOWN
  [4] HSI2_CAFLAG_PULLTYPESELECT rw — Pull-Up/Down selection for pad hsi2_caflag
    0=Pull-Down selected; 1=Pull-Up selected
  [3] HSI2_CAFLAG_PULLUDENABLE rw — Pull-Up/Down enable for pad hsi2_caflag
    values as CONTROL_CORE_PAD0_C2C_DATA12_PAD1_C2C_DATA13.C2C_DATA13_PULLUDENABLE
  [2:0] HSI2_CAFLAG_MUXMODE rw — Functional multiplexing selection for pad hsi2_caflag
    0=SEL_HSI2_CAFLAG (Select hsi2_caflag); 3=SEL_USBB1_ULPIPHY_DATA0 (Select usbb1_ulpiphy_data0); 7=SEL_SAFE_MODE_CORE56 (Select safe_mode_core56); 4=SEL_GPMC_WAIT2 (Select gpmc_wait2); 6=SEL_GPIO3_80 (Select gpio3_80)
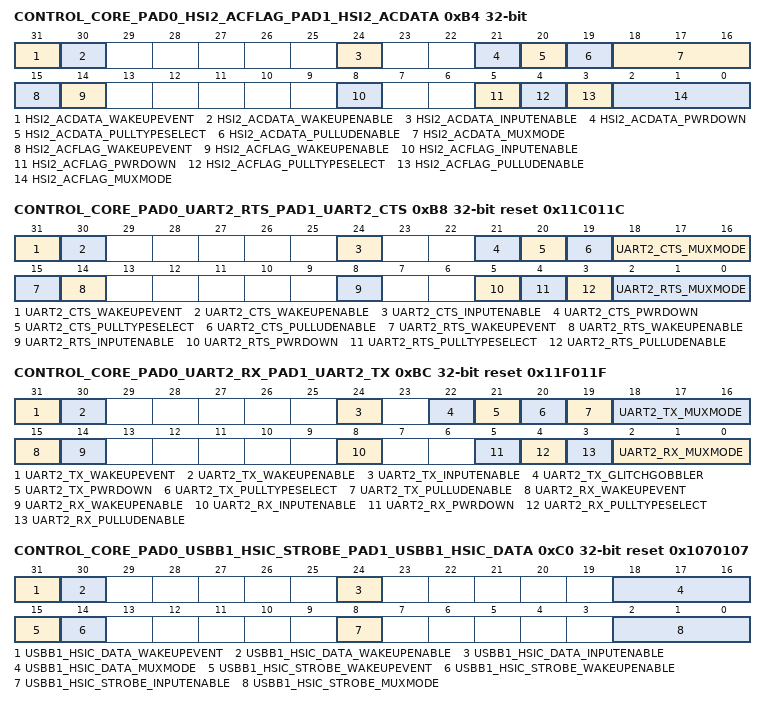
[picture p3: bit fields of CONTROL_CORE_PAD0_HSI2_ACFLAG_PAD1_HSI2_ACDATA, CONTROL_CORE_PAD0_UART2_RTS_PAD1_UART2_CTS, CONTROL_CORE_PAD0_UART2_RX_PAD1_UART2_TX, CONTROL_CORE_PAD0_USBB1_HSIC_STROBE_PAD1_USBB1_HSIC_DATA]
0xB4 CONTROL_CORE_PAD0_HSI2_ACFLAG_PAD1_HSI2_ACDATA — Register control for Pads hsi2_acflag and hsi2_acdata Access conditions. Read: unrestricted, Write: unrestricted
  [31] HSI2_ACDATA_WAKEUPEVENT ro — Pad_x wake-up event status latched in the IO
    values as CONTROL_CORE_PAD0_C2C_DATA12_PAD1_C2C_DATA13.C2C_DATA13_WAKEUPEVENT
  [30] HSI2_ACDATA_WAKEUPENABLE rw — Input pad wake-up enable
    values as CONTROL_CORE_PAD0_C2C_DATA12_PAD1_C2C_DATA13.C2C_DATA13_WAKEUPENABLE
  [24] HSI2_ACDATA_INPUTENABLE rw — Input enable value for pad hsi2_acdata
    values as CONTROL_CORE_PAD0_C2C_DATA12_PAD1_C2C_DATA13.C2C_DATA13_INPUTENABLE
  [21] HSI2_ACDATA_PWRDOWN rw — Power Down setting for pad hsi2_acdata
    values as CONTROL_CORE_PAD0_C2C_DATA12_PAD1_C2C_DATA13.C2C_DATA13_PWRDOWN
  [20] HSI2_ACDATA_PULLTYPESELECT rw — Pull-Up/Down selection for pad hsi2_acdata
    0=Pull-Down selected; 1=Pull-Up selected
  [19] HSI2_ACDATA_PULLUDENABLE rw — Pull-Up/Down enable for pad hsi2_acdata
    values as CONTROL_CORE_PAD0_C2C_DATA12_PAD1_C2C_DATA13.C2C_DATA13_PULLUDENABLE
  [18:16] HSI2_ACDATA_MUXMODE rw — Functional multiplexing selection for pad hsi2_acdata
    0=SEL_HSI2_ACDATA (Select hsi2_acdata); 3=SEL_USBB1_ULPIPHY_DATA3 (Select usbb1_ulpiphy_data3); 7=SEL_SAFE_MODE_CORE59 (Select safe_mode_core59); 4=SEL_GPMC_NCS4 (Select gpmc_ncs4); 6=SEL_GPIO3_83 (Select gpio3_83)
  [15] HSI2_ACFLAG_WAKEUPEVENT ro — Pad_x wake-up event status latched in the IO
    values as CONTROL_CORE_PAD0_C2C_DATA12_PAD1_C2C_DATA13.C2C_DATA13_WAKEUPEVENT
  [14] HSI2_ACFLAG_WAKEUPENABLE rw — Input pad wake-up enable
    values as CONTROL_CORE_PAD0_C2C_DATA12_PAD1_C2C_DATA13.C2C_DATA13_WAKEUPENABLE
  [8] HSI2_ACFLAG_INPUTENABLE rw — Input enable value for pad hsi2_acflag
    values as CONTROL_CORE_PAD0_C2C_DATA12_PAD1_C2C_DATA13.C2C_DATA13_INPUTENABLE
  [5] HSI2_ACFLAG_PWRDOWN rw — Power Down setting for pad hsi2_acflag
    values as CONTROL_CORE_PAD0_C2C_DATA12_PAD1_C2C_DATA13.C2C_DATA13_PWRDOWN
  [4] HSI2_ACFLAG_PULLTYPESELECT rw — Pull-Up/Down selection for pad hsi2_acflag
    0=Pull-Down selected; 1=Pull-Up selected
  [3] HSI2_ACFLAG_PULLUDENABLE rw — Pull-Up/Down enable for pad hsi2_acflag
    values as CONTROL_CORE_PAD0_C2C_DATA12_PAD1_C2C_DATA13.C2C_DATA13_PULLUDENABLE
  [2:0] HSI2_ACFLAG_MUXMODE rw — Functional multiplexing selection for pad hsi2_acflag
    0=SEL_HSI2_ACFLAG (Select hsi2_acflag); 3=SEL_USBB1_ULPIPHY_DATA2 (Select usbb1_ulpiphy_data2); 7=SEL_SAFE_MODE_CORE58 (Select safe_mode_core58); 4=SEL_GPMC_NCS3 (Select gpmc_ncs3); 6=SEL_GPIO3_82 (Select gpio3_82)
0xB8 CONTROL_CORE_PAD0_UART2_RTS_PAD1_UART2_CTS reset 0x11C011C — Register control for Pads uart2_rts and uart2_cts Access conditions. Read: unrestricted, Write: unrestricted
  [31] UART2_CTS_WAKEUPEVENT ro — Pad_x wake-up event status latched in the IO
    values as CONTROL_CORE_PAD0_C2C_DATA12_PAD1_C2C_DATA13.C2C_DATA13_WAKEUPEVENT
  [30] UART2_CTS_WAKEUPENABLE rw — Input pad wake-up enable
    values as CONTROL_CORE_PAD0_C2C_DATA12_PAD1_C2C_DATA13.C2C_DATA13_WAKEUPENABLE
  [24] UART2_CTS_INPUTENABLE rw — Input enable value for pad uart2_cts
    values as CONTROL_CORE_PAD0_C2C_DATA12_PAD1_C2C_DATA13.C2C_DATA13_INPUTENABLE
  [21] UART2_CTS_PWRDOWN rw — Power Down setting for pad uart2_cts
    values as CONTROL_CORE_PAD0_C2C_DATA12_PAD1_C2C_DATA13.C2C_DATA13_PWRDOWN
  [20] UART2_CTS_PULLTYPESELECT rw — Pull-Up/Down selection for pad uart2_cts
    0=Pull-Down selected; 1=Pull-Up selected
  [19] UART2_CTS_PULLUDENABLE rw — Pull-Up/Down enable for pad uart2_cts
    values as CONTROL_CORE_PAD0_C2C_DATA12_PAD1_C2C_DATA13.C2C_DATA13_PULLUDENABLE
  [18:16] UART2_CTS_MUXMODE rw — Functional multiplexing selection for pad uart2_cts
    6=SEL_GPIO3_85 (Select gpio3_85); 1=SEL_MCSPI3_CS0 (Select mcspi3_cs0); 7=SEL_SAFE_MODE_CORE61 (Select safe_mode_core61); 0=SEL_UART2_CTS (Select uart2_cts); 4=SEL_GPMC_NOE_NRE (Select gpmc_noe_nre); 5=SEL_HW_DBG17 (Select hw_dbg17); 3=SEL_USBB1_ULPIPHY_DATA5 (Select usbb1_ulpiphy_data5)
  [15] UART2_RTS_WAKEUPEVENT ro — Pad_x wake-up event status latched in the IO
    values as CONTROL_CORE_PAD0_C2C_DATA12_PAD1_C2C_DATA13.C2C_DATA13_WAKEUPEVENT
  [14] UART2_RTS_WAKEUPENABLE rw — Input pad wake-up enable
    values as CONTROL_CORE_PAD0_C2C_DATA12_PAD1_C2C_DATA13.C2C_DATA13_WAKEUPENABLE
  [8] UART2_RTS_INPUTENABLE rw — Input enable value for pad uart2_rts
    values as CONTROL_CORE_PAD0_C2C_DATA12_PAD1_C2C_DATA13.C2C_DATA13_INPUTENABLE
  [5] UART2_RTS_PWRDOWN rw — Power Down setting for pad uart2_rts
    values as CONTROL_CORE_PAD0_C2C_DATA12_PAD1_C2C_DATA13.C2C_DATA13_PWRDOWN
  [4] UART2_RTS_PULLTYPESELECT rw — Pull-Up/Down selection for pad uart2_rts
    0=Pull-Down selected; 1=Pull-Up selected
  [3] UART2_RTS_PULLUDENABLE rw — Pull-Up/Down enable for pad uart2_rts
    values as CONTROL_CORE_PAD0_C2C_DATA12_PAD1_C2C_DATA13.C2C_DATA13_PULLUDENABLE
  [2:0] UART2_RTS_MUXMODE rw — Functional multiplexing selection for pad uart2_rts
    6=SEL_GPIO3_84 (Select gpio3_84); 1=SEL_MCSPI3_SOMI (Select mcspi3_somi); 7=SEL_SAFE_MODE_CORE60 (Select safe_mode_core60); 0=SEL_UART2_RTS (Select uart2_rts); 4=SEL_GPMC_NWE (Select gpmc_nwe); 5=SEL_HW_DBG16 (Select hw_dbg16); 3=SEL_USBB1_ULPIPHY_DATA4 (Select usbb1_ulpiphy_data4)
0xBC CONTROL_CORE_PAD0_UART2_RX_PAD1_UART2_TX reset 0x11F011F — Register control for Pads uart2_rx and uart2_tx Access conditions. Read: unrestricted, Write: unrestricted
  [31] UART2_TX_WAKEUPEVENT ro — Pad_x wake-up event status latched in the IO
    values as CONTROL_CORE_PAD0_C2C_DATA12_PAD1_C2C_DATA13.C2C_DATA13_WAKEUPEVENT
  [30] UART2_TX_WAKEUPENABLE rw — Input pad wake-up enable
    values as CONTROL_CORE_PAD0_C2C_DATA12_PAD1_C2C_DATA13.C2C_DATA13_WAKEUPENABLE
  [24] UART2_TX_INPUTENABLE rw — Input enable value for pad uart2_tx
    values as CONTROL_CORE_PAD0_C2C_DATA12_PAD1_C2C_DATA13.C2C_DATA13_INPUTENABLE
  [22] UART2_TX_GLITCHGOBBLER rw — Glitch Gobbler setting for pad uart2_tx
    values as CONTROL_CORE_PAD0_HSI1_ACREADY_PAD1_HSI1_CAREADY.HSI1_ACREADY_GLITCHGOBBLER
  [21] UART2_TX_PWRDOWN rw — Power Down setting for pad uart2_tx
    values as CONTROL_CORE_PAD0_C2C_DATA12_PAD1_C2C_DATA13.C2C_DATA13_PWRDOWN
  [20] UART2_TX_PULLTYPESELECT rw — Pull-Up/Down selection for pad uart2_tx
    0=Pull-Down selected; 1=Pull-Up selected
  [19] UART2_TX_PULLUDENABLE rw — Pull-Up/Down enable for pad uart2_tx
    values as CONTROL_CORE_PAD0_C2C_DATA12_PAD1_C2C_DATA13.C2C_DATA13_PULLUDENABLE
  [18:16] UART2_TX_MUXMODE rw — Functional multiplexing selection for pad uart2_tx
    6=SEL_GPIO3_87 (Select gpio3_87); 1=SEL_MCSPI3_CLK (Select mcspi3_clk); 7=SEL_SAFE_MODE_CORE63 (Select safe_mode_core63); 0=SEL_UART2_TX (Select uart2_tx); 4=SEL_GPMC_NCS6 (Select gpmc_ncs6); 5=SEL_HW_DBG19 (Select hw_dbg19); 3=SEL_USBB1_ULPIPHY_DATA7 (Select usbb1_ulpiphy_data7)
  [15] UART2_RX_WAKEUPEVENT ro — Pad_x wake-up event status latched in the IO
    values as CONTROL_CORE_PAD0_C2C_DATA12_PAD1_C2C_DATA13.C2C_DATA13_WAKEUPEVENT
  [14] UART2_RX_WAKEUPENABLE rw — Input pad wake-up enable
    values as CONTROL_CORE_PAD0_C2C_DATA12_PAD1_C2C_DATA13.C2C_DATA13_WAKEUPENABLE
  [8] UART2_RX_INPUTENABLE rw — Input enable value for pad uart2_rx
    values as CONTROL_CORE_PAD0_C2C_DATA12_PAD1_C2C_DATA13.C2C_DATA13_INPUTENABLE
  [5] UART2_RX_PWRDOWN rw — Power Down setting for pad uart2_rx
    values as CONTROL_CORE_PAD0_C2C_DATA12_PAD1_C2C_DATA13.C2C_DATA13_PWRDOWN
  [4] UART2_RX_PULLTYPESELECT rw — Pull-Up/Down selection for pad uart2_rx
    0=Pull-Down selected; 1=Pull-Up selected
  [3] UART2_RX_PULLUDENABLE rw — Pull-Up/Down enable for pad uart2_rx
    values as CONTROL_CORE_PAD0_C2C_DATA12_PAD1_C2C_DATA13.C2C_DATA13_PULLUDENABLE
  [2:0] UART2_RX_MUXMODE rw — Functional multiplexing selection for pad uart2_rx
    6=SEL_GPIO3_86 (Select gpio3_86); 1=SEL_MCSPI3_SIMO (Select mcspi3_simo); 7=SEL_SAFE_MODE_CORE62 (Select safe_mode_core62); 0=SEL_UART2_RX (Select uart2_rx); 4=SEL_GPMC_NCS5 (Select gpmc_ncs5); 5=SEL_HW_DBG18 (Select hw_dbg18); 3=SEL_USBB1_ULPIPHY_DATA6 (Select usbb1_ulpiphy_data6)
0xC0 CONTROL_CORE_PAD0_USBB1_HSIC_STROBE_PAD1_USBB1_HSIC_DATA reset 0x1070107 — Register control for Pads usbb1_hsic_strobe and usbb1_hsic_data Access conditions. Read: unrestricted, Write: unrestricted
  [31] USBB1_HSIC_DATA_WAKEUPEVENT ro — Pad_x wake-up event status latched in the IO
    values as CONTROL_CORE_PAD0_C2C_DATA12_PAD1_C2C_DATA13.C2C_DATA13_WAKEUPEVENT
  [30] USBB1_HSIC_DATA_WAKEUPENABLE rw — Input pad wake-up enable
    values as CONTROL_CORE_PAD0_C2C_DATA12_PAD1_C2C_DATA13.C2C_DATA13_WAKEUPENABLE
  [24] USBB1_HSIC_DATA_INPUTENABLE rw — Input enable value for pad usbb1_hsic_data
    values as CONTROL_CORE_PAD0_C2C_DATA12_PAD1_C2C_DATA13.C2C_DATA13_INPUTENABLE
  [18:16] USBB1_HSIC_DATA_MUXMODE rw — Functional multiplexing selection for pad usbb1_hsic_data
    0=SEL_USBB1_HSIC_DATA (Select usbb1_hsic_data); 7=SEL_SAFE_MODE_CORE65 (Select safe_mode_core65); 6=SEL_GPIO3_93 (Select gpio3_93)
  [15] USBB1_HSIC_STROBE_WAKEUPEVENT ro — Pad_x wake-up event status latched in the IO
    values as CONTROL_CORE_PAD0_C2C_DATA12_PAD1_C2C_DATA13.C2C_DATA13_WAKEUPEVENT
  [14] USBB1_HSIC_STROBE_WAKEUPENABLE rw — Input pad wake-up enable
    values as CONTROL_CORE_PAD0_C2C_DATA12_PAD1_C2C_DATA13.C2C_DATA13_WAKEUPENABLE
  [8] USBB1_HSIC_STROBE_INPUTENABLE rw — Input enable value for pad usbb1_hsic_strobe
    values as CONTROL_CORE_PAD0_C2C_DATA12_PAD1_C2C_DATA13.C2C_DATA13_INPUTENABLE
  [2:0] USBB1_HSIC_STROBE_MUXMODE rw — Functional multiplexing selection for pad usbb1_hsic_strobe
    0=SEL_USBB1_HSIC_STROBE (Select usbb1_hsic_strobe); 7=SEL_SAFE_MODE_CORE64 (Select safe_mode_core64); 6=SEL_GPIO3_92 (Select gpio3_92)
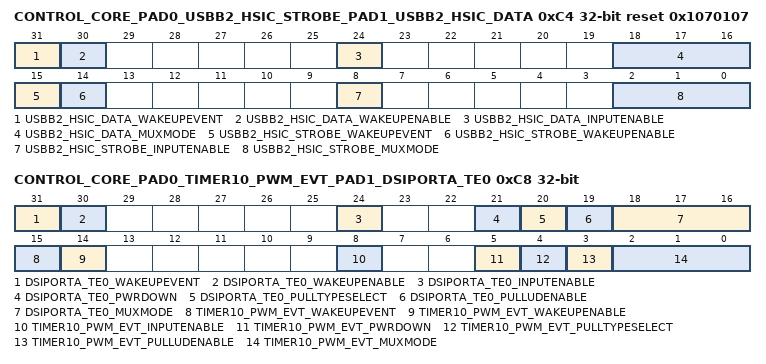
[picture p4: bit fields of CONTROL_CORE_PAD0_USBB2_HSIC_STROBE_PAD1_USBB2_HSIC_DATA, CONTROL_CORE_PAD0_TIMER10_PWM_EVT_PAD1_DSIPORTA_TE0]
0xC4 CONTROL_CORE_PAD0_USBB2_HSIC_STROBE_PAD1_USBB2_HSIC_DATA reset 0x1070107 — Register control for Pads usbb2_hsic_strobe and usbb2_hsic_data Access conditions. Read: unrestricted, Write: unrestricted
  [31] USBB2_HSIC_DATA_WAKEUPEVENT ro — Pad_x wake-up event status latched in the IO
    values as CONTROL_CORE_PAD0_C2C_DATA12_PAD1_C2C_DATA13.C2C_DATA13_WAKEUPEVENT
  [30] USBB2_HSIC_DATA_WAKEUPENABLE rw — Input pad wake-up enable
    values as CONTROL_CORE_PAD0_C2C_DATA12_PAD1_C2C_DATA13.C2C_DATA13_WAKEUPENABLE
  [24] USBB2_HSIC_DATA_INPUTENABLE rw — Input enable value for pad usbb2_hsic_data
    values as CONTROL_CORE_PAD0_C2C_DATA12_PAD1_C2C_DATA13.C2C_DATA13_INPUTENABLE
  [18:16] USBB2_HSIC_DATA_MUXMODE rw — Functional multiplexing selection for pad usbb2_hsic_data
    0=SEL_USBB2_HSIC_DATA (Select usbb2_hsic_data); 7=SEL_SAFE_MODE_CORE67 (Select safe_mode_core67); 6=SEL_GPIO3_95 (Select gpio3_95)
  [15] USBB2_HSIC_STROBE_WAKEUPEVENT ro — Pad_x wake-up event status latched in the IO
    values as CONTROL_CORE_PAD0_C2C_DATA12_PAD1_C2C_DATA13.C2C_DATA13_WAKEUPEVENT
  [14] USBB2_HSIC_STROBE_WAKEUPENABLE rw — Input pad wake-up enable
    values as CONTROL_CORE_PAD0_C2C_DATA12_PAD1_C2C_DATA13.C2C_DATA13_WAKEUPENABLE
  [8] USBB2_HSIC_STROBE_INPUTENABLE rw — Input enable value for pad usbb2_hsic_strobe
    values as CONTROL_CORE_PAD0_C2C_DATA12_PAD1_C2C_DATA13.C2C_DATA13_INPUTENABLE
  [2:0] USBB2_HSIC_STROBE_MUXMODE rw — Functional multiplexing selection for pad usbb2_hsic_strobe
    0=SEL_USBB2_HSIC_STROBE (Select usbb2_hsic_strobe); 7=SEL_SAFE_MODE_CORE66 (Select safe_mode_core66); 6=SEL_GPIO3_94 (Select gpio3_94)
0xC8 CONTROL_CORE_PAD0_TIMER10_PWM_EVT_PAD1_DSIPORTA_TE0 — Register control for Pads timer10_pwm_evt and dsiporta_te0 Access conditions. Read: unrestricted, Write: unrestricted
  [31] DSIPORTA_TE0_WAKEUPEVENT ro — Pad_x wake-up event status latched in the IO
    values as CONTROL_CORE_PAD0_C2C_DATA12_PAD1_C2C_DATA13.C2C_DATA13_WAKEUPEVENT
  [30] DSIPORTA_TE0_WAKEUPENABLE rw — Input pad wake-up enable
    values as CONTROL_CORE_PAD0_C2C_DATA12_PAD1_C2C_DATA13.C2C_DATA13_WAKEUPENABLE
  [24] DSIPORTA_TE0_INPUTENABLE rw — Input enable value for pad dsiporta_te0
    values as CONTROL_CORE_PAD0_C2C_DATA12_PAD1_C2C_DATA13.C2C_DATA13_INPUTENABLE
  [21] DSIPORTA_TE0_PWRDOWN rw — Power Down setting for pad dsiporta_te0
    values as CONTROL_CORE_PAD0_C2C_DATA12_PAD1_C2C_DATA13.C2C_DATA13_PWRDOWN
  [20] DSIPORTA_TE0_PULLTYPESELECT rw — Pull-Up/Down selection for pad dsiporta_te0
    0=Pull-Down selected; 1=Pull-Up selected
  [19] DSIPORTA_TE0_PULLUDENABLE rw — Pull-Up/Down enable for pad dsiporta_te0
    values as CONTROL_CORE_PAD0_C2C_DATA12_PAD1_C2C_DATA13.C2C_DATA13_PULLUDENABLE
  [18:16] DSIPORTA_TE0_MUXMODE rw — Functional multiplexing selection for pad dsiporta_te0
    0=SEL_DSIPORTA_TE0 (Select dsiporta_te0); 7=SEL_SAFE_MODE_CORE69 (Select safe_mode_core69); 6=SEL_GPIO6_189 (Select gpio6_189)
  [15] TIMER10_PWM_EVT_WAKEUPEVENT ro — Pad_x wake-up event status latched in the IO
    values as CONTROL_CORE_PAD0_C2C_DATA12_PAD1_C2C_DATA13.C2C_DATA13_WAKEUPEVENT
  [14] TIMER10_PWM_EVT_WAKEUPENABLE rw — Input pad wake-up enable
    values as CONTROL_CORE_PAD0_C2C_DATA12_PAD1_C2C_DATA13.C2C_DATA13_WAKEUPENABLE
  [8] TIMER10_PWM_EVT_INPUTENABLE rw — Input enable value for pad timer10_pwm_evt
    values as CONTROL_CORE_PAD0_C2C_DATA12_PAD1_C2C_DATA13.C2C_DATA13_INPUTENABLE
  [5] TIMER10_PWM_EVT_PWRDOWN rw — Power Down setting for pad timer10_pwm_evt
    values as CONTROL_CORE_PAD0_C2C_DATA12_PAD1_C2C_DATA13.C2C_DATA13_PWRDOWN
  [4] TIMER10_PWM_EVT_PULLTYPESELECT rw — Pull-Up/Down selection for pad timer10_pwm_evt
    0=Pull-Down selected; 1=Pull-Up selected
  [3] TIMER10_PWM_EVT_PULLUDENABLE rw — Pull-Up/Down enable for pad timer10_pwm_evt
    values as CONTROL_CORE_PAD0_C2C_DATA12_PAD1_C2C_DATA13.C2C_DATA13_PULLUDENABLE
  [2:0] TIMER10_PWM_EVT_MUXMODE rw — Functional multiplexing selection for pad timer10_pwm_evt
    0=SEL_TIMER10_PWM_EVT (Select timer10_pwm_evt); 7=SEL_SAFE_MODE_CORE68 (Select safe_mode_core68); 6=SEL_GPIO6_188 (Select gpio6_188)
